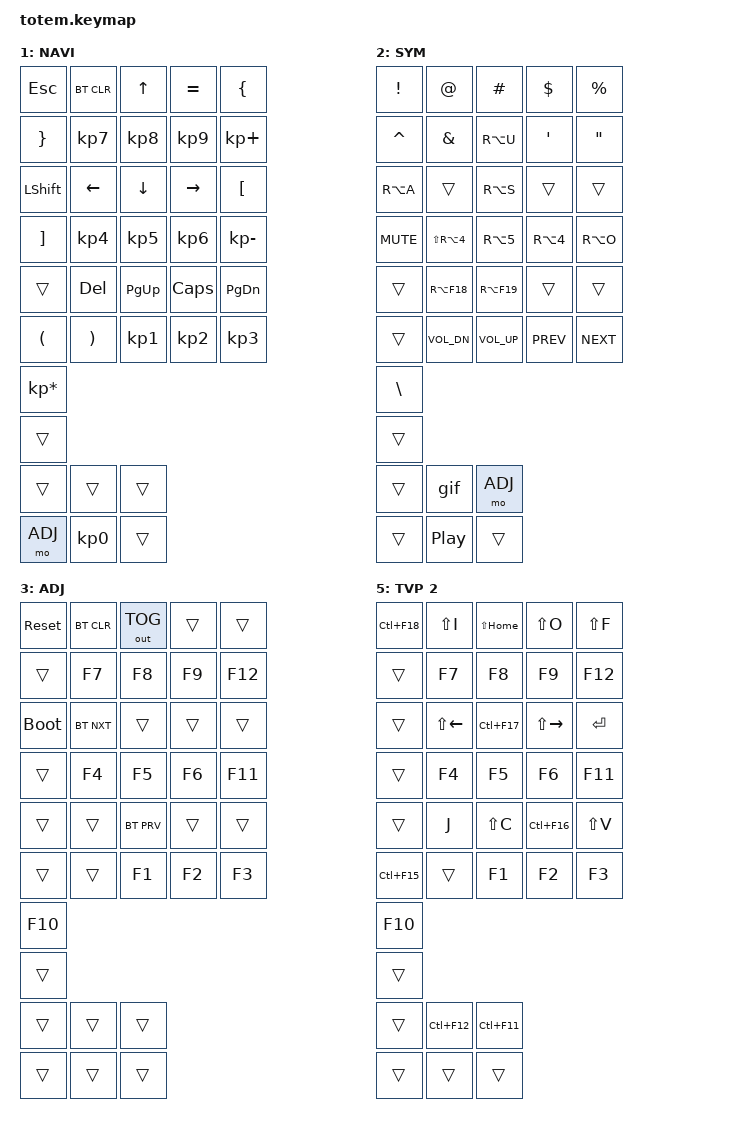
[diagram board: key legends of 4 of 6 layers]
//
//                                                        ▀▀▀▀▀     ▀▀▀▀▀          ▀▀█▀▀
//                                                        ▄▀▀▀▄  ▄  ▄▀▀▀▄  ▄  ▄▀▀▀▄  █  ▄▀▀▀▄
//                                                        █   █  █  █   █  █  █   █  █  █   █
//                                                         ▀▀▀   █   ▀▀▀   █   ▀▀▀   ▀   ▀▀▀
//                                                               █      ▄▄▄█▄▄▄    █   █  
//                                                               ▀      █  █  █     █▄█
//                                                             ▀▀▀▀▀    █  █  █      ▀
//                                                                      ▀  ▀  ▀
//
// ▄▄▄▄▄▄▄▄▄▄▄▄▄▄▄▄▄▄▄▄▄▄▄▄▄▄▄▄▄▄▄▄▄▄▄▄▄▄▄▄▄▄▄▄▄▄▄▄▄▄▄▄▄▄▄▄▄▄▄▄▄▄▄▄▄▄▄▄▄▄▄▄▄▄▄▄▄▄▄▄▄▄▄▄▄▄▄▄▄▄▄▄▄▄▄▄▄▄▄▄▄▄▄▄▄▄▄▄▄▄▄▄▄▄▄▄▄▄▄▄▄▄▄▄▄▄▄▄▄▄▄▄▄▄▄▄▄▄▄▄▄▄▄▄▄▄▄▄▄
       
#include <behaviors.dtsi>
#include <dt-bindings/zmk/keys.h>
#include <dt-bindings/zmk/bt.h>
#include <dt-bindings/zmk/outputs.h>

#define BASE 0
#define NAV  1
#define SYM  2
#define ADJ  3
#define TVP1 4
#define TVP2 5

/*
 * Timeless home-row mods
 *
 * Left hand:
 *   A = Ctrl
 *   S = Alt
 *   D = Shift
 *   F = GUI
 *
 * Right hand:
 *   J = GUI
 *   K = Shift
 *   L = Alt
 *   ; = Ctrl
 *
 * Tap = letter
 * Hold = modifier
 *
 * A hold is only triggered by keys on the opposite hand
 * or by the thumb keys.
 */

&mt {
    quick-tap-ms = <175>;
    global-quick-tap;
    flavor = "balanced";
    tapping-term-ms = <280>;
};

/ {
    behaviors {
        hml: home_row_mod_left {
            compatible = "zmk,behavior-hold-tap";
            #binding-cells = <2>;

            flavor = "balanced";
            tapping-term-ms = <280>;
            quick-tap-ms = <175>;
            require-prior-idle-ms = <150>;

            bindings = <&kp>, <&kp>;

            /* Right hand + thumbs */
            hold-trigger-key-positions =
                <5 6 7 8 9
                 15 16 17 18 19
                 26 27 28 29 30 31
                 35 36 37>;

            hold-trigger-on-release;
        };

        hmr: home_row_mod_right {
            compatible = "zmk,behavior-hold-tap";
            #binding-cells = <2>;

            flavor = "balanced";
            tapping-term-ms = <280>;
            quick-tap-ms = <175>;
            require-prior-idle-ms = <150>;

            bindings = <&kp>, <&kp>;

            /* Left hand + thumbs */
            hold-trigger-key-positions =
                <0 1 2 3 4
                 10 11 12 13 14
                 20 21 22 23 24 25
                 32 33 34>;

            hold-trigger-on-release;
        };
    };

    combos {
        compatible = "zmk,combos";

        combo_esc {
            timeout-ms = <50>;
            key-positions = <0 1>;
            bindings = <&kp ESC>;
        };

        combo_tvp {
            timeout-ms = <100>;
            key-positions = <11 12 13>;
            bindings = <&tog TVP1>;
        };
    };

    macros {
        gif: gif {
            label = "giphy";
            compatible = "zmk,behavior-macro";
            #binding-cells = <0>;
            bindings
                = <&macro_press &kp LSHFT>
                , <&macro_tap &kp N2>
                , <&macro_release &kp LSHFT>
                , <&macro_tap &kp G &kp I &kp F>
                ;
        };
    };

    keymap {
        compatible = "zmk,keymap";

        base_layer {
            label = "BASE";

            bindings = <
                /* QWERTY */
                &kp Q       &kp W       &kp E       &kp R       &kp T
                &kp Y       &kp U       &kp I       &kp O       &kp P

                /* Timeless home-row mods */
                &hml LCTRL A
                &hml LALT S
                &hml LSHFT D
                &hml LGUI F
                &kp G

                &kp H
                &hmr RGUI J
                &hmr RSHFT K
                &hmr RALT L
                &hmr RCTRL SEMI

                /* Bottom row */
                &kp Z       &kp X       &kp C       &kp V       &kp B
                &kp N       &kp M       &kp COMMA   &kp DOT     &kp FSLH
                &studio_unlock

                /* Thumbs */
                &kp DEL     &lt NAV TAB  &kp SPACE
                &kp RET     &lt SYM ESC  &kp BSPC
            >;
        };

        nav_layer {
            label = "NAVI";

            bindings = <
                &kp ESC     &bt BT_CLR  &kp UP      &kp EQUAL   &kp LBRC
                &kp RBRC    &kp KP_N7   &kp KP_N8   &kp KP_N9   &kp KP_PLUS

                &kp LSHFT   &kp LEFT    &kp DOWN    &kp RIGHT   &kp LBKT
                &kp RBKT    &kp KP_N4   &kp KP_N5   &kp KP_N6   &kp KP_MINUS

                &trans      &kp DEL     &kp PG_UP   &kp CAPS    &kp PG_DN
                &kp LPAR    &kp RPAR    &kp KP_N1   &kp KP_N2   &kp KP_N3
                &kp KP_MULTIPLY
                &trans

                &trans      &trans      &trans
                &mo ADJ     &kp KP_N0   &trans
            >;
        };

        sim_layer {
            label = "SYM";

            bindings = <
                &kp EXCL    &kp AT      &kp HASH    &kp DLLR    &kp PRCNT
                &kp CARET   &kp AMPS    &kp RA(U)   &kp SQT     &kp DQT

                &kp RA(A)   &trans      &kp RA(S)   &trans      &trans
                &kp C_MUTE  &kp LS(RA(N4)) &kp RA(N5) &kp RA(N4) &kp RA(O)

                &trans      &kp RA(F18)  &kp RA(F19) &trans      &trans
                &trans      &kp C_VOL_DN &kp C_VOL_UP &kp C_PREV &kp C_NEXT
                &kp BSLH
                &trans

                &trans      &gif        &mo ADJ
                &trans      &kp C_PP    &trans
            >;
        };

        adjust_layer {
            label = "ADJ";

            bindings = <
                &sys_reset  &bt BT_CLR  &out OUT_TOG &trans      &trans
                &trans      &kp F7      &kp F8      &kp F9      &kp F12

                &bootloader &bt BT_NXT  &trans      &trans      &trans
                &trans      &kp F4      &kp F5      &kp F6      &kp F11

                &trans      &trans      &bt BT_PRV  &trans      &trans
                &trans      &trans      &kp F1      &kp F2      &kp F3
                &kp F10
                &trans

                &trans      &trans      &trans
                &trans      &trans      &trans
            >;
        };

        tvp1_layer {
            label = "TVP 1";

            bindings = <
                &kp TAB     &kp I       &kp LC(LALT) &kp O      &kp LC(F20)
                &none       &none       &none       &none       &none

                &lt TVP2 L  &kp LEFT    &kp LALT    &kp RIGHT   &kp SPACE
                &none       &none       &none       &none       &none

                &kp J       &kp LSHFT   &kp LC(C)   &kp BSPC    &kp LC(V)
                &kp LC(F19) &none       &none       &none       &none
                &none

                &trans      &kp LC(F14) &kp LC(F13)
                &none       &none       &none
            >;
        };

        tvp2_layer {
            label = "TVP 2";

            bindings = <
                &kp LC(F18) &kp LS(I)   &kp LS(HOME) &kp LS(O)   &kp LS(F)
                &trans      &kp F7      &kp F8      &kp F9      &kp F12

                &trans      &kp LS(LEFT) &kp LC(F17) &kp LS(RIGHT) &kp RET
                &trans      &kp F4       &kp F5      &kp F6       &kp F11

                &trans      &kp J       &kp LS(C)   &kp LC(F16) &kp LS(V)
                &kp LC(F15) &trans      &kp F1      &kp F2      &kp F3
                &kp F10
                &trans

                &trans      &kp LC(F12) &kp LC(F11)
                &trans      &trans      &trans
            >;
        };
    };
};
